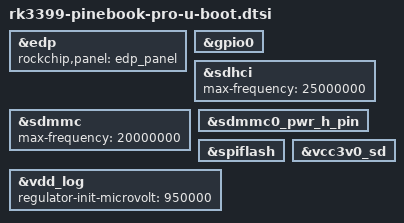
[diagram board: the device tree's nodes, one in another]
// SPDX-License-Identifier: GPL-2.0+
/*
 * Copyright (C) 2019 Peter Robinson <pbrobinson at gmail.com>
 */

#include "rk3399-u-boot.dtsi"
#include "rk3399-sdram-lpddr4-100.dtsi"

&edp {
	rockchip,panel = <&edp_panel>;
};

&gpio0 {
	bootph-pre-ram;
};

&sdhci {
	max-frequency = <25000000>;
};

&sdmmc {
	max-frequency = <20000000>;
};

&sdmmc0_pwr_h_pin {
	bootph-pre-ram;
};

&spiflash {
	bootph-pre-ram;
	bootph-some-ram;
};

&vcc3v0_sd {
	bootph-pre-ram;
};

&vdd_log {
	regulator-init-microvolt = <950000>;
};
